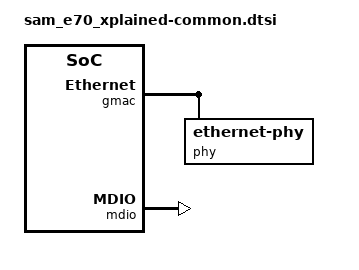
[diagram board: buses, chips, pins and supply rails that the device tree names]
/*
 * Copyright (c) 2017 Piotr Mienkowski
 * Copyright (c) 2017 Justin Watson
 * Copyright (c) 2020 Stephanos Ioannidis <root@stephanos.io>
 * Copyright (c) 2020 Gerson Fernando Budke <nandojve@gmail.com>
 *
 * SPDX-License-Identifier: Apache-2.0
 */

#include "sam_s70_xplained-common.dtsi"

&gmac {
	status = "okay";

	phy: phy {
		compatible = "ethernet-phy";
		status = "okay";
		address = <0>;
		mdio = <&mdio>;
	};
};

&mdio {
	status = "okay";
};
